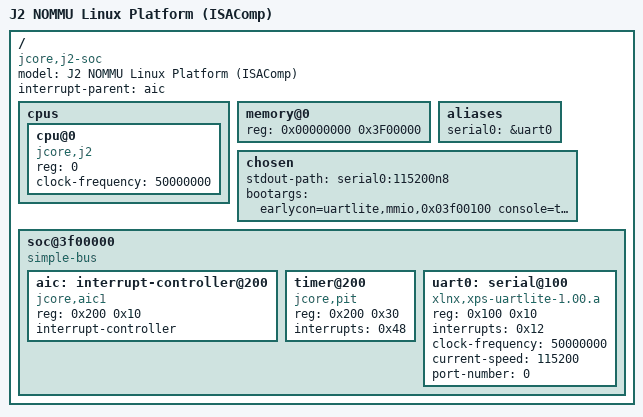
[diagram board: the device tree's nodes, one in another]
// SPDX-License-Identifier: GPL-2.0
// Device tree for J2 processor generated by ISAComp
/dts-v1/;

/ {
	compatible = "jcore,j2-soc";
	model = "J2 NOMMU Linux Platform (ISAComp)";

	#address-cells = <1>;
	#size-cells = <1>;

	interrupt-parent = <&aic>;

	cpus {
		#address-cells = <1>;
		#size-cells = <0>;

		cpu@0 {
			device_type = "cpu";
			compatible = "jcore,j2";
			reg = <0>;
			clock-frequency = <50000000>;  // 50 MHz
		};
	};

	// 63MB memory starting at 0x00000000
	// Initrd loaded at 0x03800000 by testbench (kernel reserves via memblock)
	// 0x03F00000-0x03FFFFFF: Reserved for peripherals
	// Kernel loads at 0x00002000, VBR at 0x00000000
	memory@0 {
		device_type = "memory";
		reg = <0x00000000 0x3F00000>;  // 63MB
	};

	aliases {
		serial0 = &uart0;
	};

	chosen {
		stdout-path = "serial0:115200n8";
		bootargs = "earlycon=uartlite,mmio,0x03f00100 console=ttyUL0,115200";
		// Initramfs is built into the kernel via CONFIG_INITRAMFS_SOURCE
	};

	// Peripheral region at top of 64MB address space
	// 0x03F00000 - 0x03FFFFFF (1MB)
	soc@3f00000 {
		compatible = "simple-bus";
		ranges = <0 0x03f00000 0x100000>;

		#address-cells = <1>;
		#size-cells = <1>;

		// JCORE AIC (Advanced Interrupt Controller)
		// Compatible with Linux irq-jcore-aic driver
		aic: interrupt-controller@200 {
			compatible = "jcore,aic1";
			reg = <0x200 0x10>;
			interrupt-controller;
			#interrupt-cells = <1>;
		};

		// JCORE PIT (Programmable Interval Timer)
		// Compatible with Linux jcore-pit driver
		// NOTE: PIT and AIC share the same base address (0x200)
		// They use different register offsets within that space:
		//   AIC: 0x08 (INTPRI)
		//   PIT: 0x00 (PITEN), 0x10 (THROT), 0x14 (COUNT), 0x18 (BUSPD), etc.
		timer@200 {
			compatible = "jcore,pit";
			reg = <0x200 0x30>;
			interrupts = <0x48>;  // IRQ 72 (0x48)
		};

		// Xilinx UARTLite serial port
		// Compatible with Linux uartlite driver
		// UART base at 0x03F00100, TX at 0x03F00104
		uart0: serial@100 {
			compatible = "xlnx,xps-uartlite-1.00.a";
			reg = <0x100 0x10>;
			interrupts = <0x12>;  // IRQ 18
			clock-frequency = <50000000>;
			current-speed = <115200>;
			device_type = "serial";
			port-number = <0>;
		};
	};
};
